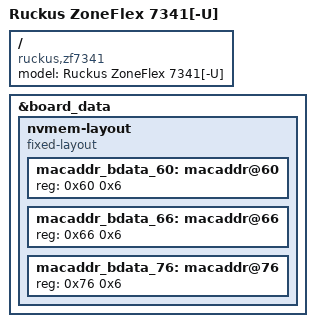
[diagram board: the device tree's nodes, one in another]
// SPDX-License-Identifier: GPL-2.0-or-later OR MIT

#include "ar7161_ruckus_zf734x.dtsi"

/ {
	model = "Ruckus ZoneFlex 7341[-U]";
	compatible = "ruckus,zf7341", "qca,ar7161";
};

&board_data {
	nvmem-layout {
		compatible = "fixed-layout";
		#address-cells = <1>;
		#size-cells = <1>;

		macaddr_bdata_60: macaddr@60 {
			reg = <0x60 0x6>;
		};

		macaddr_bdata_66: macaddr@66 {
			reg = <0x66 0x6>;
		};

		macaddr_bdata_76: macaddr@76 {
			reg = <0x76 0x6>;
		};
	};
};
